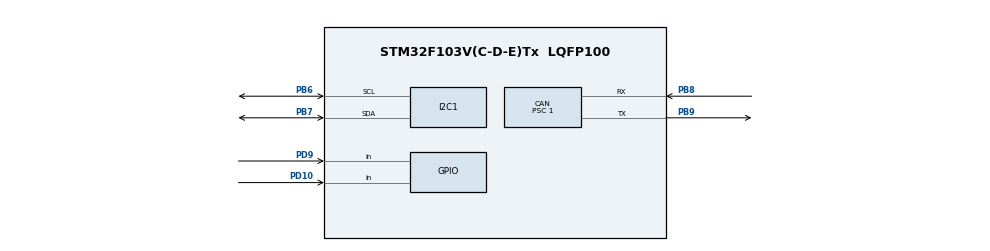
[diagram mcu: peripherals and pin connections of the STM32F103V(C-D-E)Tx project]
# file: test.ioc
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CAN.BS1=CAN_BS1_11TQ
CAN.BS2=CAN_BS2_4TQ
CAN.CalculateBaudRate=500000
CAN.CalculateTimeBit=2000
CAN.CalculateTimeQuantum=125.0
CAN.Prescaler=1
CAN.SJW=CAN_SJW_1TQ
Mcu.Family=STM32F1
Mcu.Name=STM32F103V(C-D-E)Tx
Mcu.Package=LQFP100
NVIC.PriorityGroup=NVIC_PRIORITYGROUP_4
NVIC.TIM1_UP_IRQn=true\:0\:0\:false\:false\:true\:true\:true\:true
PA13.Mode=Serial_Wire
PA13.Signal=SYS_JTMS-SWDIO
PA14.Mode=Serial_Wire
PA14.Signal=SYS_JTCK-SWCLK
PB6.Mode=I2C
PB6.Signal=I2C1_SCL
PB7.Mode=I2C
PB7.Signal=I2C1_SDA
PB8.Mode=CAN_Activate
PB8.Signal=CAN_RX
PB9.Mode=CAN_Activate
PB9.Signal=CAN_TX
PD10.GPIO_PuPd=GPIO_PULLUP
PD10.Signal=GPIO_Input
PD9.GPIO_PuPd=GPIO_PULLUP
PD9.Signal=GPIO_Input
ProjectManager.HeapSize=0x200
ProjectManager.StackSize=0x400
ProjectManager.TargetToolchain=MDK-ARM V5.32
RCC.APB1Freq_Value=8000000
RCC.APB2Freq_Value=8000000
TIM1.AutoReloadPreload=TIM_AUTORELOAD_PRELOAD_ENABLE
TIM1.Period=999
TIM1.Prescaler=7
VP_TIM1_VS_ClockSourceINT.Mode=Internal
board=custom

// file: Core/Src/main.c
/* USER CODE BEGIN Header */
/**
  ******************************************************************************
  * @file           : main.c
  * @brief          : Main program body
  ******************************************************************************
  * @attention
  *
  * Copyright (c) 2026 STMicroelectronics.
  * All rights reserved.
  *
  * This software is licensed under terms that can be found in the LICENSE file
  * in the root directory of this software component.
  * If no LICENSE file comes with this software, it is provided AS-IS.
  *
  ******************************************************************************
  */
/* USER CODE END Header */
#include "main.h"

/* USER CODE BEGIN Includes */
#include "Bl_Rte.h"
#include "Bl_TaskSchedule.h"
#include "OLED.h"
/* USER CODE END Includes */

CAN_HandleTypeDef hcan;

I2C_HandleTypeDef hi2c1;

TIM_HandleTypeDef htim1;

void SystemClock_Config(void);
static void MX_GPIO_Init(void);
static void MX_I2C1_Init(void);
static void MX_TIM1_Init(void);
static void MX_CAN_Init(void);

int main(void)
{

  /* MCU Configuration--------------------------------------------------------*/

  /* Reset of all peripherals, Initializes the Flash interface and the Systick. */
  HAL_Init();

  /* Configure the system clock */
  SystemClock_Config();

  /* Initialize all configured peripherals */
  MX_GPIO_Init();
  MX_I2C1_Init();
  MX_TIM1_Init();
  MX_CAN_Init();
  /* USER CODE BEGIN 2 */
  Bl_Rte_Init();
  OLED_ShowString(1, 1, "hello S world");

  Bl_TaskSchedule_MainFunction();
  /* USER CODE END 2 */

  /* Infinite loop */
  while (1)
  {

  }
}

void SystemClock_Config(void)
{
  RCC_OscInitTypeDef RCC_OscInitStruct = {0};
  RCC_ClkInitTypeDef RCC_ClkInitStruct = {0};

  /** Initializes the RCC Oscillators according to the specified parameters
  * in the RCC_OscInitTypeDef structure.
  */
  RCC_OscInitStruct.OscillatorType = RCC_OSCILLATORTYPE_HSI;
  RCC_OscInitStruct.HSIState = RCC_HSI_ON;
  RCC_OscInitStruct.HSICalibrationValue = RCC_HSICALIBRATION_DEFAULT;
  RCC_OscInitStruct.PLL.PLLState = RCC_PLL_NONE;
  if (HAL_RCC_OscConfig(&RCC_OscInitStruct) != HAL_OK)
  {
    Error_Handler();
  }

  /** Initializes the CPU, AHB and APB buses clocks
  */
  RCC_ClkInitStruct.ClockType = RCC_CLOCKTYPE_HCLK|RCC_CLOCKTYPE_SYSCLK
                              |RCC_CLOCKTYPE_PCLK1|RCC_CLOCKTYPE_PCLK2;
  RCC_ClkInitStruct.SYSCLKSource = RCC_SYSCLKSOURCE_HSI;
  RCC_ClkInitStruct.AHBCLKDivider = RCC_SYSCLK_DIV1;
  RCC_ClkInitStruct.APB1CLKDivider = RCC_HCLK_DIV1;
  RCC_ClkInitStruct.APB2CLKDivider = RCC_HCLK_DIV1;

  if (HAL_RCC_ClockConfig(&RCC_ClkInitStruct, FLASH_LATENCY_0) != HAL_OK)
  {
    Error_Handler();
  }
}

static void MX_CAN_Init(void)
{

  hcan.Instance = CAN1;
  hcan.Init.Prescaler = 1;
  hcan.Init.Mode = CAN_MODE_NORMAL;
  hcan.Init.SyncJumpWidth = CAN_SJW_1TQ;
  hcan.Init.TimeSeg1 = CAN_BS1_11TQ;
  hcan.Init.TimeSeg2 = CAN_BS2_4TQ;
  hcan.Init.TimeTriggeredMode = DISABLE;
  hcan.Init.AutoBusOff = DISABLE;
  hcan.Init.AutoWakeUp = DISABLE;
  hcan.Init.AutoRetransmission = DISABLE;
  hcan.Init.ReceiveFifoLocked = DISABLE;
  hcan.Init.TransmitFifoPriority = DISABLE;
  if (HAL_CAN_Init(&hcan) != HAL_OK)
  {
    Error_Handler();
  }

}

static void MX_I2C1_Init(void)
{

  hi2c1.Instance = I2C1;
  hi2c1.Init.ClockSpeed = 100000;
  hi2c1.Init.DutyCycle = I2C_DUTYCYCLE_2;
  hi2c1.Init.OwnAddress1 = 0;
  hi2c1.Init.AddressingMode = I2C_ADDRESSINGMODE_7BIT;
  hi2c1.Init.DualAddressMode = I2C_DUALADDRESS_DISABLE;
  hi2c1.Init.OwnAddress2 = 0;
  hi2c1.Init.GeneralCallMode = I2C_GENERALCALL_DISABLE;
  hi2c1.Init.NoStretchMode = I2C_NOSTRETCH_DISABLE;
  if (HAL_I2C_Init(&hi2c1) != HAL_OK)
  {
    Error_Handler();
  }

}

static void MX_TIM1_Init(void)
{

  TIM_ClockConfigTypeDef sClockSourceConfig = {0};
  TIM_MasterConfigTypeDef sMasterConfig = {0};

  htim1.Instance = TIM1;
  htim1.Init.Prescaler = 7;
  htim1.Init.CounterMode = TIM_COUNTERMODE_UP;
  htim1.Init.Period = 999;
  htim1.Init.ClockDivision = TIM_CLOCKDIVISION_DIV1;
  htim1.Init.RepetitionCounter = 0;
  htim1.Init.AutoReloadPreload = TIM_AUTORELOAD_PRELOAD_ENABLE;
  if (HAL_TIM_Base_Init(&htim1) != HAL_OK)
  {
    Error_Handler();
  }
  sClockSourceConfig.ClockSource = TIM_CLOCKSOURCE_INTERNAL;
  if (HAL_TIM_ConfigClockSource(&htim1, &sClockSourceConfig) != HAL_OK)
  {
    Error_Handler();
  }
  sMasterConfig.MasterOutputTrigger = TIM_TRGO_RESET;
  sMasterConfig.MasterSlaveMode = TIM_MASTERSLAVEMODE_DISABLE;
  if (HAL_TIMEx_MasterConfigSynchronization(&htim1, &sMasterConfig) != HAL_OK)
  {
    Error_Handler();
  }

}

static void MX_GPIO_Init(void)
{
  GPIO_InitTypeDef GPIO_InitStruct = {0};

  /* GPIO Ports Clock Enable */
  __HAL_RCC_GPIOD_CLK_ENABLE();
  __HAL_RCC_GPIOA_CLK_ENABLE();
  __HAL_RCC_GPIOB_CLK_ENABLE();

  /*Configure GPIO pins : PD9 PD10 */
  GPIO_InitStruct.Pin = GPIO_PIN_9|GPIO_PIN_10;
  GPIO_InitStruct.Mode = GPIO_MODE_INPUT;
  GPIO_InitStruct.Pull = GPIO_PULLUP;
  HAL_GPIO_Init(GPIOD, &GPIO_InitStruct);

}

void Error_Handler(void)
{
  __disable_irq();
  while (1)
  {
  }
}
